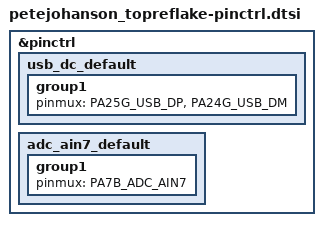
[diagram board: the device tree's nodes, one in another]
/*
 * Copyright (c) 2022, Gerson Fernando Budke <nandojve@gmail.com>
 * SPDX-License-Identifier: Apache-2.0
 */

#include <dt-bindings/pinctrl/samd21-da1gXabcd-pinctrl.h>

&pinctrl {
	usb_dc_default: usb_dc_default {
		group1 {
			pinmux = <PA25G_USB_DP>,
				 <PA24G_USB_DM>;
		};
	};

	adc_ain7_default: adc_ain7_default {
		group1 {
			pinmux = <PA7B_ADC_AIN7>;
		};
	};
};

